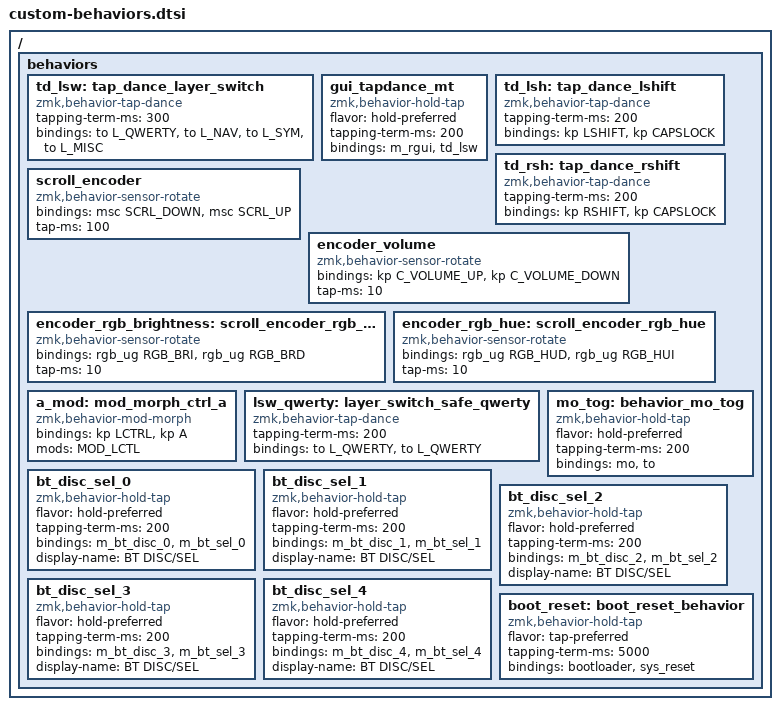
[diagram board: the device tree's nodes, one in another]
/ {
    behaviors {
        
        // Tap-dance behavior to switch layers (1-tap --> layer0, 2-tap --> layer1 ...)
        td_lsw: tap_dance_layer_switch {
            compatible = "zmk,behavior-tap-dance";
            #binding-cells = <0>;
            tapping-term-ms = <300>;
            bindings = <&to L_QWERTY>, <&to L_NAV>, <&to L_SYM>, <&to L_MISC>;
        };

        gui_tapdance_mt: gui_tapdance_mt {
            compatible = "zmk,behavior-hold-tap";
            #binding-cells = <2>;
            flavor = "hold-preferred";
            tapping-term-ms = <200>;
            bindings = <&m_rgui &td_lsw>;
        };
        
        // Tap-dance behavior for LShift, (1-tap --> normal shift, 2-tap --> CapsLock)
        td_lsh: tap_dance_lshift {
            compatible = "zmk,behavior-tap-dance";
            #binding-cells = <0>;
            tapping-term-ms = <200>;
            bindings = <&kp LSHIFT>, <&kp CAPSLOCK>;
        };
        
        // Tap-dance behavior for RShift, (1-tap --> normal shift, 2-tap --> CapsLock)
        td_rsh: tap_dance_rshift {
            compatible = "zmk,behavior-tap-dance";
            #binding-cells = <0>;
            tapping-term-ms = <200>;
            bindings = <&kp RSHIFT>, <&kp CAPSLOCK>;
        };
        
        // Knob encoder scroll behavior
        scroll_encoder: scroll_encoder {
            compatible = "zmk,behavior-sensor-rotate";
            #sensor-binding-cells = <0>;
            bindings = <&msc SCRL_DOWN>, <&msc SCRL_UP>;
            tap-ms = <100>;
        };

        // Knob encoder volume control behavior
        encoder_volume: encoder_volume {
            compatible = "zmk,behavior-sensor-rotate";
            #sensor-binding-cells = <0>;
            bindings = <&kp C_VOLUME_UP>, <&kp C_VOLUME_DOWN>;
            tap-ms = <10>;
        };
        
        // Knob encoder rgb brightness change
        encoder_rgb_brightness: scroll_encoder_rgb_brightness {
            compatible = "zmk,behavior-sensor-rotate";
            #sensor-binding-cells = <0>;
            bindings = <&rgb_ug RGB_BRI>, <&rgb_ug RGB_BRD>;
            tap-ms = <10>;
        };

        // Knob encoder rgb hue change
        encoder_rgb_hue: scroll_encoder_rgb_hue {
            compatible = "zmk,behavior-sensor-rotate";
            #sensor-binding-cells = <0>;
            bindings = <&rgb_ug RGB_HUD>, <&rgb_ug RGB_HUI>;
            tap-ms = <10>;
        };
        
        // CTRL + A (Select All) Mod morph behavior (if LCTRL is pressed --> A, else --> LCTRL)
        a_mod: mod_morph_ctrl_a {
            compatible = "zmk,behavior-mod-morph";
            #binding-cells = <0>;
            bindings = <&kp LCTRL>, <&kp A>;
            mods = <MOD_LCTL>;
        };

        // Double-tap layer behavior, reset to QWERTY layer
        lsw_qwerty: layer_switch_safe_qwerty {
            compatible = "zmk,behavior-tap-dance";
            #binding-cells = <0>;
            tapping-term-ms = <200>;
            bindings = <&to L_QWERTY>, <&to L_QWERTY>;
        };

        // Hold-tap layer behavior
        mo_tog: behavior_mo_tog {
            compatible = "zmk,behavior-hold-tap";
            #binding-cells = <2>;
            flavor = "hold-preferred";
            tapping-term-ms = <200>;
            bindings = <&mo>, <&to>;
        };

        // Bluetooth disconnect-select profile hold behaviors (hold -> disconnect, tap -> select)
        bt_disc_sel_0: bt_disc_sel_0 {
            compatible = "zmk,behavior-hold-tap";
            #binding-cells = <2>;
            flavor = "hold-preferred";
            tapping-term-ms = <200>;
            bindings = <&m_bt_disc_0 &m_bt_sel_0>;
            display-name = "BT DISC/SEL";
        };
        bt_disc_sel_1: bt_disc_sel_1 {
            compatible = "zmk,behavior-hold-tap";
            #binding-cells = <2>;
            flavor = "hold-preferred";
            tapping-term-ms = <200>;
            bindings = <&m_bt_disc_1 &m_bt_sel_1>;
            display-name = "BT DISC/SEL";
        };
        bt_disc_sel_2: bt_disc_sel_2 {
            compatible = "zmk,behavior-hold-tap";
            #binding-cells = <2>;
            flavor = "hold-preferred";
            tapping-term-ms = <200>;
            bindings = <&m_bt_disc_2 &m_bt_sel_2>;
            display-name = "BT DISC/SEL";
        };
        bt_disc_sel_3: bt_disc_sel_3 {
            compatible = "zmk,behavior-hold-tap";
            #binding-cells = <2>;
            flavor = "hold-preferred";
            tapping-term-ms = <200>;
            bindings = <&m_bt_disc_3 &m_bt_sel_3>;
            display-name = "BT DISC/SEL";
        };
        bt_disc_sel_4: bt_disc_sel_4 {
            compatible = "zmk,behavior-hold-tap";
            #binding-cells = <2>;
            flavor = "hold-preferred";
            tapping-term-ms = <200>;
            bindings = <&m_bt_disc_4 &m_bt_sel_4>;
            display-name = "BT DISC/SEL";
        };
                
        // Bootloader long press - reset tap
        boot_reset: boot_reset_behavior { 
            compatible = "zmk,behavior-hold-tap";
            #binding-cells = <2>;
            flavor = "tap-preferred";
            tapping-term-ms = <5000>;
            bindings = <&bootloader &sys_reset>;
        };
    };
};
